# STM32H747xG_CM4 register map
File version: 1.0
Registers are 32-bit, read-write, reset 0x0 unless marked. A register's access mark holds for its fields unless they carry their own. Offsets are from the block's base; [hi:lo] are bit positions.

## SWPMI1 — Single Wire Protocol Master Interface SPWMI
Base 0x40008800
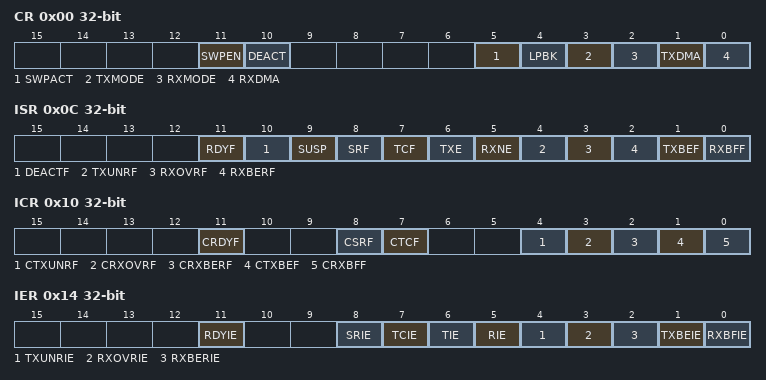
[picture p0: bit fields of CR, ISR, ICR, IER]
0x00 CR — SWPMI Configuration/Control register
  [11] SWPEN — Single wire protocol master transceiver enable
  [10] DEACT — Single wire protocol master interface deactivate
  [5] SWPACT — Single wire protocol master interface activate
  [4] LPBK — Loopback mode enable
  [3] TXMODE — Transmission buffering mode
    0=SINGLE (Single software buffer mode for transmission); 1=MULTI (Multi software buffermode for transmission)
  [2] RXMODE — Reception buffering mode
    0=SINGLE (Single software buffer mode for reception); 1=MULTI (Multi software buffermode for reception)
  [1] TXDMA — Transmission DMA enable
  [0] RXDMA — Reception DMA enable
0x04 BRR — SWPMI bitrate register
  [7:0] BR — BR[7:0] bits (Bitrate prescaler)
0x0C ISR — SWPMI Interrupt and Status register
  [11] RDYF — Transceiver ready flag
  [10] DEACTF — DEACTIVATED flag
  [9] SUSP — SUSPEND flag
  [8] SRF — Slave resume flag
  [7] TCF — Transfer complete flag
  [6] TXE — Transmit data register empty
  [5] RXNE — Receive data register not empty
  [4] TXUNRF — Transmit underrun error flag
  [3] RXOVRF — Receive overrun error flag
  [2] RXBERF — Receive CRC error flag
  [1] TXBEF — Transmit buffer empty flag
  [0] RXBFF — Receive buffer full flag
0x10 ICR — SWPMI Interrupt Flag Clear register
  [11] CRDYF — Clear transceiver ready flag
  [8] CSRF — Clear slave resume flag
  [7] CTCF — Clear transfer complete flag
  [4] CTXUNRF — Clear transmit underrun error flag
  [3] CRXOVRF — Clear receive overrun error flag
  [2] CRXBERF — Clear receive CRC error flag
  [1] CTXBEF — Clear transmit buffer empty flag
  [0] CRXBFF — Clear receive buffer full flag
0x14 IER — SWPMI Interrupt Enable register
  [11] RDYIE — Transceiver ready interrupt enable
  [8] SRIE — Slave resume interrupt enable
  [7] TCIE — Transmit complete interrupt enable
  [6] TIE — Transmit interrupt enable
  [5] RIE — Receive interrupt enable
  [4] TXUNRIE — Transmit underrun error interrupt enable
  [3] RXOVRIE — Receive overrun error interrupt enable
  [2] RXBERIE — Receive CRC error interrupt enable
  [1] TXBEIE — Transmit buffer empty interrupt enable
  [0] RXBFIE — Receive buffer full interrupt enable
0x18 RFL — SWPMI Receive Frame Length register
  [4:0] RFL — RFL[4:0] bits (Receive Frame length)
0x1C TDR — SWPMI Transmit data register
  [31:0] TD — Transmit Data Register
0x20 RDR — SWPMI Receive data register
  [31:0] RD — Receive Data Register
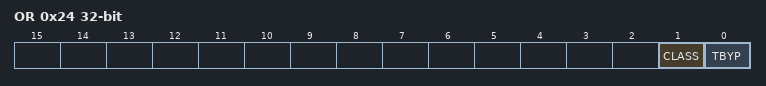
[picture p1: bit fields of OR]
0x24 OR — SWPMI Option register
  [1] CLASS — SWP CLASS selection
    0=C (SWPMI_IO uses directly VDD voltage to operate in class C); 1=B (SWPMI_IO uses an internal voltage regulator to operate in class B)
  [0] TBYP — SWP Transceiver Bypass

## OPAMP — Operational Amplifier (OPAMP)
Base 0x40009000
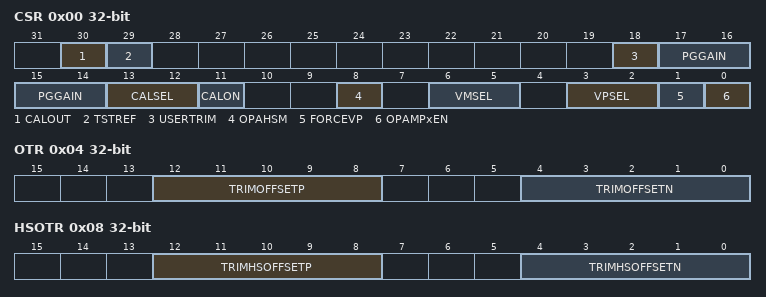
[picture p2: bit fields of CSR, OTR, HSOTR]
0x00 CSR — OPAMP control/status register
  [30] CALOUT — Operational amplifier calibration output
  [29] TSTREF — OpAmp calibration reference voltage output control
  [18] USERTRIM — User trimming enable
    0=FACTORY (OPAMP trimming factors set to factory values); 1=USER (OPAMP trimming factors set to user values)
  [17:14] PGGAIN — Operational amplifier Programmable amplifier gain value
  [13:12] CALSEL — Calibration selection
  [11] CALON — Calibration mode enable
    0=FUNCTIONAL (OPAMP functional mode); 1=CALIBRATION (OPAMP calibration mode)
  [8] OPAHSM — Operational amplifier high speed mode
  [6:5] VMSEL — Inverting input selection
    0=IO0; 1=IO1; 2=CONNECT_NO
  [3:2] VPSEL — Non inverted input selection
    0=IO0; 1=DAC
  [1] FORCEVP — Force internal reference on VP
  [0] OPAMPxEN — OPAMP enable
0x04 OTR — OPAMP
  [12:8] TRIMOFFSETP — Trim for PMOS differential pairs
  [4:0] TRIMOFFSETN — Trim for NMOS differential pairs
0x08 HSOTR — OPAMP
  [12:8] TRIMHSOFFSETP — Trim for PMOS differential pairs
  [4:0] TRIMHSOFFSETN — Trim for NMOS differential pairs
